# BlueNRG1 register map
Vendor: STMicroelectronics; Series: BlueNRG1; File version: 2.0.0
CPU: CM0 r0p0, little endian, no MPU, no FPU, 2 interrupt priority bits
Registers are 32-bit, read-write, reset 0x0 unless marked. A register's access mark holds for its fields unless they carry their own. Offsets are from the block's base; [hi:lo] are bit positions; 'fields as' and 'values as' point back to an identical list; <NAME> marks a mode.

## I2C2
Base 0x40A00000
Same registers: I2C1 0x40B00000
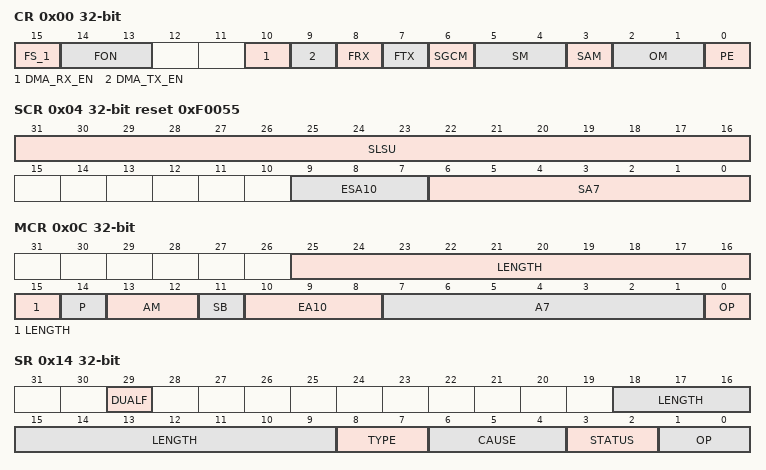
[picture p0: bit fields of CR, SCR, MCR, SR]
0x00 CR — I2C Control register
  [15] FS_1 — Force stop enable bit. When set to 1b, the STOP condition is generated.<ul><li>0: Force stop disabled.</li><li>1: Enable force stop.</li></ul>
    0=DISABLE (Force stop disable); 1=ENABLE (Force stop enable)
  [14:13] FON — Filtering on sets the digital filters on the SDA, SCL line, according to the I2C bus requirements, when standard open-drain pads are used:<ul><li>00b: No digital filters are inserted.</li><li>01b: Digital filters (filter 1 ck wide spikes) are inserted.</li><li>10b: Digital filters (filter 2 ck wide spikes) are inserted.</li><li>11b: Digital filters (filter 4 ck wide spikes) are inserted.</li></ul>
    0=NONE (No digital filters are inserted); 1=CK1_SPIKES (Digital filters (filter 1 ck wide spikes) are inserted); 2=CK2_SPIKES (Digital filters (filter 2 ck wide spikes) are inserted); 3=CK4_SPIKES (Digital filters (filter 4 ck wide spikes) are inserted)
  [10] DMA_RX_EN — Enables the DMA RX interface.<ul><li>0: Idle state, the DMA RX interface is disabled.</li><li>1: Run state, the DMA RX interface is enabled.</li></ul>On the completion of the DMA transfer, the DMA RX interface is automatically turned off clearing this bit when the end of transfer signal coming from the DMA is raised. DMA_TX_EN and DMA_RX_EN must not enabled at the same time.
    0=DISABLE (DMA RX interface disable); 1=ENABLE (DMA RX interface enable)
  [9] DMA_TX_EN — Enables the DMA TX interface.<ul><li>0: Idle state, the DMA TX interface is disabled.</li><li>1: Run state, the DMA TX interface is enabled.</li></ul>On the completion of the DMA transfer, the DMA TX interface is automatically turned off clearing this bit when the end of transfer signal coming from the DMA is raised. DMA_TX_EN and DMA_RX_EN must not enabled at the same time.
    0=DISABLE (DMA TX interface disable); 1=ENABLE (DMA TX interface enable)
  [8] FRX write-1-sets — FRX flushes the receive circuitry (FIFO, fsm).The configuration of the I2C node (register setting) is not affected by the flushing operation. The flushing operation is performed on modules working on different clock domains (system and I2C clocks) and needs several system clock cycles before to be completed. Upon completion, the I2C node (internal logic) clears this bit. The application must not access the Rx FIFO during the flushing operation and should poll on this bit waiting for the completion.<ul><li>0: Flush operation is completed (I2C controller clears the bit).</li><li>1: Flush operation is started and in progress (set by application).</li></ul>
  [7] FTX write-1-sets — FTX flushes the transmit circuitry (FIFO, fsm). The configuration of the I2C node (register setting) is not affected by the flushing operation. The flushing operation is performed on modules working on different clock domains (system and I2C clocks) and needs several system clock cycles before being completed. Upon completion, the I2C node (internal logic) clears this bit. The application must not access the Tx FIFO during the flushing operation and should poll on this bit waiting for completion.<ul><li>0: Flush operation is completed (I2C controller clears the bit).</li><li>1: Flush operation is started and in progress (set by application).</li></ul>
  [6] SGCM — Slave general call mode defines the operating mode of the slave controller when a general call is received. This setting does not affect the hardware general call that is always managed in transparent mode.<ul><li>0: transparent mode, the slave receiver recognizes the general call but any action is taken by the hardware after the decoding of the message included in the Rx FIFO.</li><li>1: direct mode, the slave receiver recognizes the general call and executes directly (without software intervention) the related actions. Only the status code word is stored in the I2C_SR register for notification to the application.</li></ul>
    0=TRANSPARENT_MODE (Transparent mode, the slave receiver recognizes the general call ut any action is taken by software after the decoding of the message included in the Rx FIFO); 1=DIRECT_MODE (Direct mode, the slave receiver recognizes the general call and executes directly (without software intervention) the related actions. Only the status code word is stored in the SR register for notification to the application)
  [5:4] SM — Speed mode. SM defines the speed mode related to the serial bit rate:<ul><li>0: Standard mode (up to 100 K/s).</li><li>1: Fast mode (up to 400 K/s).</li></ul>
    0=STANDARD_MODE (Standard mode (up to 100 K/s)); 1=FAST_MODE (Fast mode (up to 400 K/s))
  [3] SAM — Slave addressing mode. SAM defines the slave addressing mode when the peripheral works in slave or master/slave mode. The received address is compared with the content of the register SCR.<ul><li>0: 7-bit addressing mode.</li><li>1: 10-bit addressing mode.</li></ul>
    0=ADDR_7BIT (7-bit addressing mode); 1=ADDR_10BIT (10-bit addressing mode)
  [2:1] OM — Select the operating mode:<ul><li>00b: Slave mode. The peripheral can only respond (transmit/receive) when addressed by a master device</li><li>01b: Master mode. The peripheral works in a multi-master system where itself cannot be addressed by another master device. It can only initiate a new transfer as master device.</li><li>10b: Master/slave mode. The peripheral works in a multi-master system where itself can be addressed by another master device, besides to initiate a transfer as master device.</li></ul>
    0=SLAVE (The peripheral can only respond (transmit/receive) when addressed by a master device); 1=MASTER (The peripheral works in a multi-master system where itself cannot be addressed by another master device. It can only initiate a new transfer as master device); 2=MASTER_SLAVE (The peripheral works in a multi-master system where itself can be addressed by another master device, besides to initiate a transfer as master device)
  [0] PE — I2C enable disable:<ul><li>0: I2C disable.</li><li>1: I2C enable.</li></ul>This bit when deasserted works as software reset for I2C peripheral.
    0=DISABLE (I2C disable); 1=ENABLE (I2C enable)
0x04 SCR reset 0xF0055 — I2C Slave Control register
  [31:16] SLSU — Slave data setup time. SLSU defines the data setup time after SCL clock stretching in terms of i2c_clk cycles. Data setup time is actually equal to SLSU-1 clock cycles. The typical values for i2c_clk of 16 MHz are SLSU = 5 in standard mode and SLSU = 3 in fast modes.
  [9:7] ESA10 — Extended slave address 10-bit. ESA10 includes the extension (MSB bits) to the SA7 register field in case of slave addressing mode set to 10-bit
  [6:0] SA7 — Slave address 7-bit. SA7 includes the slave address 7-bit or the LSB bits of the slave address 10-bit
0x0C MCR — I2C master control register
  [25:15] LENGTH — Transaction length. Defines the length, in terms of the number of bytes to be transmitted (MW) or received (MR). In case of write operation, the payload is stored in the Tx FIFO. A transaction can be larger than the Tx FIFO size. In case of read operation the length refers to the number of bytes to be received before generating a not-acknowledge response. A transaction can be larger than the Rx FIFO size. The I2C clock line is stretched low until the data in Rx FIFO are consumed.
  [14] P — Stop condition:<ul><li>0: The current transaction is not terminated by a STOP condition. A repeated START condition is generated on the next operation which is required to avoid to stall the I2C line.</li><li>1: The current transaction is terminated by a STOP condition.</li></ul>
  [13:12] AM — Address type:<ul><li>00b: The transaction is initiated by a general call command. In this case the fields OP, A7, EA10 are "don't care".</li><li>01b: The transaction is initiated by the 7-bit address included in the A7 field.</li><li>10b: The transaction is initiated by the 10-bit address included in the EA10 and A7 fields.</li></ul>
    0=GENERAL_CALL (The transaction is initiated by a general call command); 1=BIT7_ADDRESS (The transaction is initiated by the 7-bit address included in the A7 field); 2=BIT10_ADDRESS (The transaction is initiated by the 10-bit address included in the EA10 and A7 fields)
  [11] SB — Start byte:<ul><li>0: The start byte procedure is not applied to the current transaction.</li><li>1: The start byte procedure is prefixed to the current transaction.</li></ul>
  [10:8] EA10 — Extended address. Includes the extension (MSB bits) of the field A7 used to initiate the current transaction
  [7:1] A7 — Address. Includes the 7-bit address or the LSB bits of the10-bit address used to initiate the current transaction
  [0] OP — Operation<ul><li>0: Indicates a master write operation.</li><li>1: Indicates a master read operation.</li></ul>
    0=MASTER_WRITE (Indicates a master write operation); 1=MASTER_READ (Indicates a master read operation)
0x10 TFR 8-bit — I2C transmit FIFO register
  [7:0] TDATA — Transmission Data. TDATA contains the payload related to a master write or read-from-slave operation to be written in the Tx FIFO. TDATA(0) is the first LSB bit transmitted over the I2C line.<p>In case of master write operation, the Tx FIFO shall be preloaded otherwise the I2C controller cannot start the operation until data are available.</p><p>In case of read-from-slave operation, when the slave is addressed, the interrupt RISR:RFSR bit is asserted and the CPU shall download the data in the FIFO. If the FIFO is empty and the I2C master is still requiring data, a new request (RISR:RFSE interrupt bit) is asserted to require additional data to the CPU. The slave controller stretches the I2C clock line when no data are available for transmission. Since the Tx FIFO could contain some pending data related to the previous transfer (the transfer length may be unknown to the slave controller), the Tx FIFO is self-flushed before asserting the I2C_RISR:RFSR bit. Upon completion of the read-from-slave operation the interrupt bit I2C_RISR:STD is asserted and the related status of the operation is stored in the I2C_SR register. In CPU mode, the FIFO management shall be based on the assertion of the interrupt bit RISR:TXFNE, related to the nearly-empty threshold.</p><p>In DMA mode, the single/burst requests are automatically executed based on the number of entries available in the TX FIFO and the related destination burst size programmed in the I2C_DMAR:DBSIZE_TX register field. The DMA requests are terminated at the end of the I2C read operation (notacknowledge received by the master) by a dummy last single/burst request.</p>
0x14 SR ro — I2C status register
  [29] DUALF — Dual flag (slave mode):<ul><li>0: Received address matched with slave address (SA7).</li><li>1: Received address matched with dual slave address (DSA7).</li></ul>Cleared by hardware after a Stop condition or repeated Start condition, bus error or when PE=0.
    0=DUAL_SLAVE_ADDR_OFF (Received address matched with slave address (SA7)); 1=DUAL_SLAVE_ADDR_ON (Received address matched with dual slave address (DSA7))
  [18:9] LENGTH — Transfer length. For an MR, WTS operation the LENGTH field defines the actual size of the subsequent payload, in terms of number of bytes. For an MW, RFS operation the LENGTH field defines the actual number of bytes transferred by the master/slave device. For a WTS operation if the transfer length exceeds 2047 bytes, the operation is stopped by the slave returning a NACK handshake and the flag OVFL is set. For an RFS operation if the transfer length exceeds 2047 bytes, the operation continues normally but the LENGTH field is reset to 0.
  [8:7] TYPE — Receive type. Valid only for the operation WTS:<ul><li>00b: FRAME: The slave has received a normal frame.</li><li>01b: GCALL: The slave has received a general call. If the it I2C_CR:SGCM is set to 1, the general call is directly executed without software intervention and only the control code word is reported in FIFO (LENGTH =0).</li><li>10b: HW_GCALL: The slave has received a hardware general call.</li></ul>
    0=FRAME (The slave has received a normal frame); 1=GCALL (The slave has received a general call); 2=HW_GCALL (The slave has received a hardware general call)
  [6:4] CAUSE — Abort cause. This field is valid only when the STATUS field contains the ABORT tag. Others: RESERVED. <ul><li>000b: NACK_ADDR: The master receives a not-acknowledge after the transmission of the address. Valid for the operation MW, MR.</li><li>001b: NACK_DATA: The master receives a not-acknowledge during the data phase of a MW operation. Valid for the operation MW.</li><li>011b: ARB_LOST: The master loses the arbitration during a MW or MR operation. Valid for the operation MW, MR.</li><li>100b: BERR_START: Slave restarts, a START Condition occurs while the byte transfer is not terminated.</li><li>101b: BERR_STOP: Slave reset, a STOP Condition while the byte transfer is not terminated.</li><li>110b: OVFL: The slave receives a frame related to the WTS operation longer than the maximum size = 2047 bytes. In this case the slave device returns a NACK to complete the data transfer. Valid for WTS operation</li></ul>
    0=NACK_ADDR (The master receives a not-acknowledge after the transmission of the address); 1=NACK_DATA (The master receives a not-acknowledge during the data phase of a MW operation); 3=ARB_LOST (The master loses the arbitration during a MW or MR operation); 4=BERR_START (Slave restarts, a START Condition occurs while the byte transfer is not terminated); 5=BERR_STOP (Slave reset, a STOP Condition while the byte transfer is not terminated); 6=OVFL (The slave receives a frame related to the WTS operation longer than the maximum size = 2047 bytes)
  [3:2] STATUS — Controller status. Valid for the operations MW, MR, WTS RFS:<ul><li>00b: NOP: No operation is in progress.</li><li>01b: ON_GOING: An operation is ongoing.</li><li>10b: OK: The operation (OP field) has been completed successfully.</li><li>11b: ABORT: The operation (OP field) has been aborted due to the occurrence of the event described in the CAUSE field.</li></ul>
    0=NOP (No operation is in progress); 1=ON_GOING (An operation is ongoing); 2=OK (The operation (OP field) has been completed successfully); 3=ABORT (The operation (OP field) has been aborted due to the occurrence of the event descried in the CAUSE field)
  [1:0] OP — Operation:<ul><li>00b: MW: master write operation.</li><li>01b: MR: master read operation.</li><li>10b: WTS: write-to-slave operation.</li><li>11b: RFS: read-from-slave operation.</li></ul>
    0=MW (Master write operation); 1=MR (Master read operation); 2=WTS (Write to slave operation); 3=RFS (Read from slave operation)
0x18 RFR 8-bit ro — I2C receive FIFO register
  [7:0] RDATA — Receive data. RDATA contains the received payload, related to a master read or write-to-slave operation, to be read from the Rx FIFO. The RDATA(0) is the first LSB bit received over the I2C line. In case the FIFO is full, the I2C controller stretches automatically the I2C clock line until a new entry is available.<p>For a write-to-slave operation, when the slave is addressed, the interrupt I2C_RISR:WTSR bit is asserted for notification to the CPU. In CPU mode the FIFO management shall be based on the assertion of the interrupt bit I2C_RISR:RXFNF, related to the nearly-full threshold.</p><p>In DMA mode, the single requests are automatically executed based on the number of entries contained in the Rx FIFO.</p>
0x1C TFTR 16-bit — I2C transmit FIFO threshold register
  [9:0] THRESH_TX — Threshold TX, contains the threshold value, in terms of number of bytes, of the Tx FIFO.<p>When the number of entries of the Tx FIFO is less or equal than the threshold value, the interrupt bit I2C_RISR:TXFNE is set in order to request the loading of data to the application.</p>
0x20 RFTR 16-bit — I2C receive FIFO threshold register
  [9:0] THRESH_RX — Threshold RX, contains the threshold value, in terms of number of bytes, of the Rx FIFO.<p>When the number of entries of the RX FIFO is greater than or equal to the threshold value, the interrupt bit RISR:RXFNF is set in order to request the download of received data to the application. The application shall download the received data based on the threshold. (RISR:RXFNF).</p>
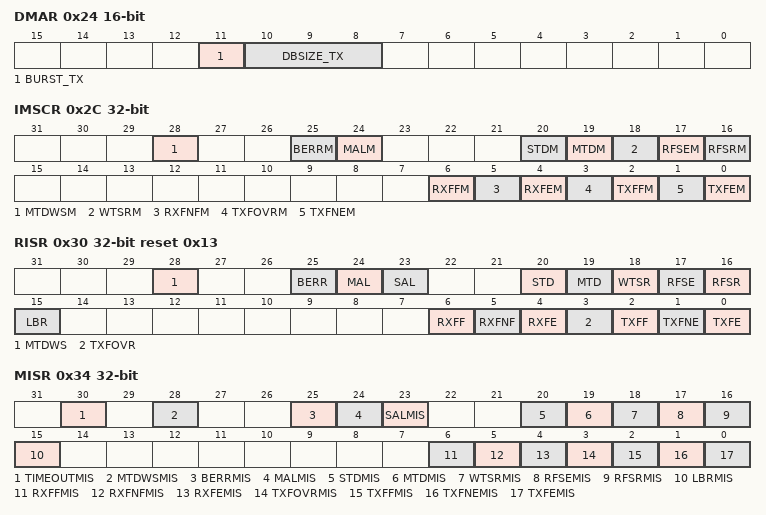
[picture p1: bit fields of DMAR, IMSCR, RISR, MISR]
0x24 DMAR 16-bit — I2C DMA register
  [11] BURST_TX — Defines the type of DMA request generated by the DMA TX interface.<ul><li>0: Single request mode. Transfers a single data (one byte) in the TX FIFO.</li><li>1: Burst request mode. Transfers a programmed burst of data according to DBSIZE_TX field.</li></ul>When the burst mode is programmed, the DMA transfer can be completed by one or more single requests as required.
  [10:8] DBSIZE_TX — Destination burst size. This register field is valid only if the BURST_TX bit is set to '1'. If burst size is smaller than the transaction length, only single request are generated.
0x28 BRCR 16-bit reset 0x8 — I2C Baud-rate counter register
  [15:0] BRCNT — Baud rate counter. BRCNT defines the counter value used to set up the I2C baud rate in standard and fast mode, when the peripheral is operating in master mode.
0x2C IMSCR — I2C interrupt mask set/clear register
  [28] MTDWSM — Master Transaction done without stop mask. MTDWSM enables the interrupt bit MTDWS:<ul><li>0: MTDWS interrupt is disabled.</li><li>1: MTDWS interrupt is enabled.</li></ul>
    0=DISABLE (Disable the interrupt mask); 1=ENABLE (Enable the interrupt mask)
  [25] BERRM — Bus Error mask. BERRM enables the interrupt bit BERR:<ul><li>0: BERR interrupt is disabled.</li><li>1: BERR interrupt is enabled.</li></ul>
    values as MTDWSM
  [24] MALM — Master Arbitration lost mask. MALM enables the interrupt bit MAL:<ul><li>0: MAL interrupt is disabled.</li><li>1: MAL interrupt is enabled.</li></ul>
    values as MTDWSM
  [20] STDM — Slave Transaction done mask. STDM enables the interrupt bit STD:<ul><li>0: STDM interrupt is disabled.</li><li>1: STDM interrupt is enabled.</li></ul>
    values as MTDWSM
  [19] MTDM — Master Transaction done mask. MTDM enables the interrupt bit MTD:<ul><li>0: MTD interrupt is disabled.</li><li>1: MTD interrupt is enabled.</li></ul>
    values as MTDWSM
  [18] WTSRM — Write-to-Slave request mask. WTSRM enables the interrupt bit WTSR:<ul><li>0: WTSR interrupt is disabled.</li><li>1: WTSR interrupt is enabled.</li></ul>
    values as MTDWSM
  [17] RFSEM — Read-from-Slave empty mask. RFSEM enables the interrupt bit RFSE:<ul><li>0: RFSE interrupt is disabled.</li><li>1: RFSE interrupt is enabled.</li></ul>
    values as MTDWSM
  [16] RFSRM — Read-from-Slave request mask. RFSRM enables the interrupt bit RFSR:<ul><li>0: RFSR interrupt is disabled.</li><li>1: RFSR interrupt is enabled.</li></ul>
    0=DISABLE (Disable the interrupt mask); 1=ENABLE (Enable the interrupt mask); 0=DISABLE (Disable the interrupt mask); 1=ENABLE (Enable the interrupt mask)
  [6] RXFFM — RX FIFO full mask. RXFFM enables the interrupt bit RXFF:<ul><li>0: RXFF interrupt is disabled.</li><li>1: RXFF interrupt is enabled.</li></ul>
    values as MTDWSM
  [5] RXFNFM — RX FIFO nearly full mask. RXNFM enables the interrupt bit RXNF:<ul><li>0: RXNF interrupt is disabled.</li><li>1: RXNF interrupt is enabled</li></ul>
    values as MTDWSM
  [4] RXFEM — RX FIFO empty mask. RXFEM enables the interrupt bit RXFE:<ul><li>0: RXFE interrupt is disabled.</li><li>1: RXFE interrupt is enabled.</li></ul>
    values as MTDWSM
  [3] TXFOVRM — TX FIFO overrun mask. TXOVRM enables the interrupt bit TXOVR:<ul><li>0: TXOVR interrupt is disabled.</li><li>1: TXOVR interrupt is enabled.</li></ul>
    values as MTDWSM
  [2] TXFFM — TX FIFO full mask. TXFFM enables the interrupt bit TXFF:<ul><li>0: TXFF interrupt is disabled.</li><li>1: TXFF interrupt is enabled.</li></ul>
    values as MTDWSM
  [1] TXFNEM — TX FIFO nearly empty mask. TXFNEM enables the interrupt bit TXFNE:<ul><li>0: TXFNE interrupt is disabled.</li><li>1: TXFNE interrupt is enabled.</li></ul>
    values as MTDWSM
  [0] TXFEM — TX FIFO empty mask. TXFEM enables the interrupt bit TXFE:<ul><li>0: TXFE interrupt is disabled.</li><li>1: TXFE interrupt is enabled.</li></ul>
    values as MTDWSM
0x30 RISR ro reset 0x13 — I2C raw interrupt status register
  [28] MTDWS — Master transaction done without stop. MTDWS is set when a master operation (write or read) has been executed and a stop (MCR:P field) is not programmed. The application shall read the related transaction status (SR register), the pending data in the RX FIFO (only for a master read operation) and clear this interrupt (transaction acknowledgment). A subsequent master operation can be issued (by writing the MCR register) after clearing this interrupt. A subsequent slave operation will be notified (RISR:WTSR and RISR:RFSR interrupt bits assertion) after clearing this interrupt, meanwhile the I2C clock line will be stretched low. This interrupt is cleared by setting the related bit of the ICR register:<ul><li>0: Master transaction acknowledged.</li><li>1: Master transaction done (ready for acknowledgment) and stop is not applied into the I2C bus.</li></ul>
  [25] BERR — Bus Error. BERR is set when an unexpected Start/Stop condition occurs during a transaction. The related actions are different, depending on the type of operation in progress.The status code word in the SR contains a specific error tag (CAUSE field) for this error condition. This interrupt is cleared by setting the related bit of the ICR register.<ul><li>0: No bus error detection.</li><li>1: Bus error detection.</li></ul>
  [24] MAL — Master arbitration lost. MAL is set when the master loses the arbitration. The status code word in the SR contains a specific error tag (CAUSE field) for this error condition. A collision occurs when 2 stations transmit simultaneously 2 opposite values on the serial line. The station that is pulling up the line, identifies the collision reading a 0 value on the sda_in signal, stops the transmission, leaves the bus and waits for the idle state (STOP condition received) on the bus line before retrying the same transaction. The station which transmits the first unique zero wins the bus arbitration. This interrupt is cleared by setting the related bit of the ICR register.<ul><li>0: No master arbitration lost.</li><li>1: Master arbitration lost.</li></ul>
  [23] SAL — Slave Arbitration lost. SAL is set when the slave loses the arbitration during the data phase. A collision occurs when 2 devices transmit simultaneously 2 opposite values on the serial data line. The device that is pulling up the line, identifies the collision reading a 0 value on the sda_in signal, stops the transmission, releases the bus and waits for the idle state (STOP condition received) on the bus line. The device which transmits the first unique zero wins the bus arbitration. This interrupt is cleared by setting the related bit of the ICR register.<ul><li>0: No slave arbitration lost.</li><li>1: Slave arbitration lost.</li></ul>
  [20] STD — Slave Transaction done. STD is set when a slave operation (write-to-slave or read-from-slave) has been executed. The application shall read the related transaction status (SR register), the pending data in the RX FIFO (only for a write-to-slave operation) and clear this interrupt (transaction acknowledgment). A subsequent slave operation will be notified (RISR:WTSR and RISR:RFSR interrupt bits assertion) after clearing this interrupt, meanwhile the I2C clock line will be stretched low. A subsequent master operation can be issued (by writing the MCR register) after clearing this interrupt. This interrupt is cleared by setting the related bit of the ICR register:<ul><li>0: Slave transaction acknowledged.</li><li>1: Slave transaction done (ready for acknowledgment).</li></ul>
  [19] MTD — Master Transaction done. MTD is set when a master operation (master write or master read) has been executed after a stop condition. The application shall read the related transaction status (SR register), the pending data in the RX FIFO (only for a master read operation) and clear this interrupt (transaction acknowledgment). A subsequent master operation can be issued (writing the MCR register) after the clearing of this interrupt. A subsequent slave operation will be notified (RISR:WTSR and RISR:RFSR interrupt bits assertion) after clearing this interrupt, meanwhile the I2C clock line will be stretched low. This interrupt is cleared by setting the related bit of the ICR register.<ul><li>0: Master transaction acknowledged.</li><li>1: Master transaction done (ready for acknowledgment).</li></ul>
  [18] WTSR — Write-to-Slave request. WTSR is set when a write-to-slave operation is received (I2C slave is addressed) from the I2C line. This notification can be used by the application to program the DMA descriptor when required. This interrupt is cleared by setting the related bit of the ICR register:<ul><li>0: No write-to-slave request pending.</li><li>1: Write-to-slave request is pending.</li></ul>
  [17] RFSE — Read-from-Slave empty. RFSE is set when a read-from-slave operation is in progress and TX FIFO is empty. On the assertion of this interrupt, the CPU shall download in TX FIFO the data required for the slave operation. This bit is self-cleared by writing in TX FIFO. At the end of the read-from-slave operation this bit is cleared although the TX FIFO is empty.<ul><li>0: TX FIFO is not empty.</li><li>1: TX FIFO is empty with the read-from-slave operation in progress.</li></ul>
  [16] RFSR — Read-from-slave request. RFSR is set when a read-from-slave "Slavetransmitter" request is received (I2C slave is addressed) from the I2C line. On the assertion of this interrupt the TX FIFO is flushed (pending data are cleared) and the CPU shall put the data in TX FIFO. This bit is self-cleared by writing data in FIFO. In case the FIFO is empty before the completion of the read operation, the RISR:RFSE interrupt bit is set.This interrupt is cleared by setting the related bit of the ICR register.<ul><li>0: Read-from-slave request has been served.</li><li>1: Read-from-slave request is pending.</li></ul>
  [15] LBR — Length number of bytes received. LBR is set in case of MR or WTS and when the number of bytes received is equal to the transaction length programmed in the MCR:LENGTH (master mode) or SMB_SCR:LENGTH (slave mode). On the assertion of this interrupt and when the bit CR:FRC_STRTCH is set, the hardware starts clock stretching, the CPU shall download the data byte (Command code, Byte Count, Data...) from RX FIFO, re-set the expected length of the transaction in SMB_SCR:LENGTH and clear the interrupt. When clearing this interrupt the hardware continues the transfer. This interrupt is cleared by setting the related bit of the ICR register.<ul><li>0: Length number of bytes is not received.</li><li>1: Length number of bytes is received.</li></ul>
  [6] RXFF — RX FIFO full. RXFF is set when a full condition occurs in RX FIFO. This bit is self-cleared when the data are read from the RX FIFO.<ul><li>0: RX FIFO is not full.</li><li>1: RX FIFO is full.</li></ul>
  [5] RXFNF — RX FIFO nearly full. RXFNF is set when the number of entries in RX FIFO is greater than or equal to the threshold value programmed in the RFTR:THRESHOLD_RX register. Its self-cleared when the threshold level is under the programmed threshold:<ul><li>0: Number of entries in the RX FIFO less than the RFTR:THRESHOLD_RX register.</li><li>1: Number of entries in the RX FIFO greater than or equal to the RFTR:THRESHOLD_RX register.</li></ul>
  [4] RXFE — RX FIFO empty. RXFE is set when the RX FIFO is empty. This bit is self-cleared when the slave RX FIFO is not empty:<ul><li>0: RX FIFO is not empty..</li><li>1: RX FIFO is empty..</li></ul>
  [3] TXFOVR — TX FIFO overrun. TXFOVR is set when a write operation in TX FIFO is performed and TX FIFO is full. The application must avoid an overflow condition by a proper data flow control. Anyway in case of overrun, the application shall flush the transmitter (CR:FTX bit to set) because the TX FIFO content is corrupted (at least one word has been lost in FIFO). This interrupt is cleared by setting the related bit of the ICR register:<ul><li>0: No overrun condition occurred in TX FIFO.</li><li>1: Overrun condition occurred in TX FIFO.</li></ul>
  [2] TXFF — TX FIFO full. TXFF is set when a full condition occurs in TX FIFO. This bit is self-cleared when the TX FIFO is not full:<ul><li>0: TX FIFO is not full.</li><li>1: TX FIFO is full.</li></ul>
  [1] TXFNE — TX FIFO nearly empty. TXFNE is set when the number of entries in TX FIFO is less than or equal to the threshold value programmed in the I2C_TFTR:THRESHOLD_TX register. It is self-cleared when the threshold level is over the programmed threshold.<ul><li>0: Number of entries in TX FIFO greater than the TFTR:THRESHOLD_TX register.</li><li>1: Number of entries in TX FIFO less than or equal to the TFTR:THRESHOLD_TX register.</li></ul>
  [0] TXFE — TX FIFO empty. TXFE is set when TX FIFO is empty. This bit is self-cleared by writing in TX FIFO.<ul><li>0: TX FIFO is not empty.</li><li>1: TX FIFO is empty.</li></ul>
0x34 MISR ro — I2C masked interrupt status register
  [30] TIMEOUTMIS — Timeout or Tlow error masked interrupt status.<ul><li>0: No timeout error.</li><li>1: SCL remained LOW for 25 ms (Timeout).</li></ul>
  [28] MTDWSMIS — Master Transaction done without stop masked interrupt status.<ul><li>0: Master transaction acknowledged.</li><li>1: Master transaction done (ready for acknowledgment) and stop is not applied into the I2C bus.</li></ul>
  [25] BERRMIS — Bus Error masked interrupt status.<ul><li>0: No bus error detection.</li><li>1: Bus error detection.</li></ul>
  [24] MALMIS — Master Arbitration lost masked interrupt status.<ul><li>0: No master arbitration lost.</li><li>1: Master arbitration lost.</li></ul>
  [23] SALMIS — Slave Arbitration lost masked interrupt status.<ul><li>0: No slave arbitration lost.</li><li>1: Slave arbitration lost.</li></ul>
  [20] STDMIS — Slave Transaction done masked interrupt status.<ul><li>0: Slave transaction acknowledged.</li><li>1: Slave transaction done (ready for acknowledgment).</li></ul>
  [19] MTDMIS — Master Transaction done masked interrupt status.<ul><li>0: Master transaction acknowledged.</li><li>1: Master transaction done (ready for acknowledgment).</li></ul>
  [18] WTSRMIS — Write-to-Slave request masked interrupt status.<ul><li>0: No write-to-slave request pending.</li><li>1: Write-to-slave request is pending.</li></ul>
  [17] RFSEMIS — Read-from-Slave empty masked interrupt status.<ul><li>0: TX FIFO is not empty.</li><li>1: TX FIFO is empty with the read-from-slave operation in progress.</li></ul>
  [16] RFSRMIS — Read-from-Slave request masked interrupt status.<ul><li>0: Read-from-slave request has been served.</li><li>1: Read-from-slave request is pending.</li></ul>
  [15] LBRMIS — Length number of bytes received masked interrupt status.<ul><li>0: Length number of bytes is not received.</li><li>1: Length number of bytes is received.</li></ul>
  [6] RXFFMIS — RX FIFO full masked interrupt status.<ul><li>0: RX FIFO is not full.</li><li>1: RX FIFO is full.</li></ul>
  [5] RXFNFMIS — RX FIFO nearly full masked interrupt status.<ul><li>0: Number of entries in the RX FIFO less than the RFTR:THRESHOLD_RX register.</li><li>1: Number of entries in the RX FIFO greater than or equal to the RFTR:THRESHOLD_RX register.</li></ul>
  [4] RXFEMIS — RX FIFO empty masked interrupt status.<ul><li>0: RX FIFO is not empty.</li><li>1: RX FIFO is empty..</li></ul>
  [3] TXFOVRMIS — Tx FIFO overrun masked interrupt status.<ul><li>0: No overrun condition occurred in TX FIFO.</li><li>1: Overrun condition occurred in TX FIFO.</li></ul>
  [2] TXFFMIS — Tx FIFO full masked interrupt status.<ul><li>0: TX FIFO is not full.</li><li>1: TX FIFO is full.</li></ul>
  [1] TXFNEMIS — TX FIFO nearly empty masked interrupt status.<ul><li>0: Number of entries in TX FIFO greater than the TFTR:THRESHOLD_TX register.</li><li>1: Number of entries in TX FIFO less than or equal to the TFTR:THRESHOLD_TX register.</li></ul>
  [0] TXFEMIS — TX FIFO empty masked interrupt status.<ul><li>0: TX FIFO is not empty.</li><li>1: TX FIFO is empty.</li></ul>
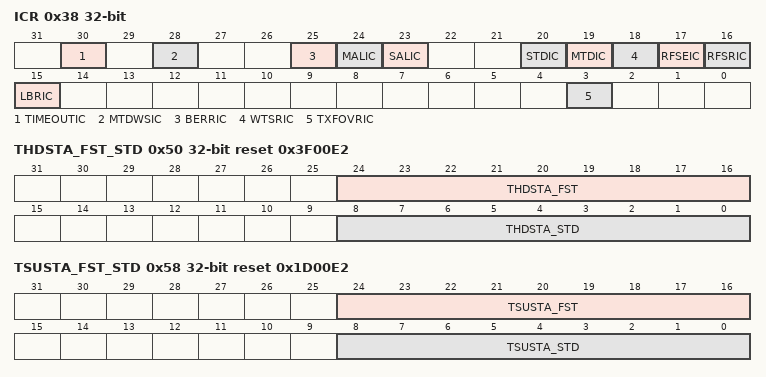
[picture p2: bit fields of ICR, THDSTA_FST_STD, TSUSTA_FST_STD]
0x38 ICR write-1-clears — I2C interrupt clear register
  [30] TIMEOUTIC — Timeout or Tlow error interrupt clear.<ul><li>0: Has no effect.</li><li>1: Clears interrupt pending.</li></ul>
  [28] MTDWSIC — Master Transaction done without stop interrupt clear.<ul><li>0: Has no effect.</li><li>1: Clears interrupt pending.</li></ul>
  [25] BERRIC — Bus Error interrupt clear.<ul><li>0: Has no effect.</li><li>1: Clears interrupt pending.</li></ul>
  [24] MALIC — Master Arbitration lost interrupt clear.<ul><li>0: Has no effect.</li><li>1: Clears interrupt pending.</li></ul>
  [23] SALIC — Slave Arbitration lost interrupt clear.<ul><li>0: Has no effect.</li><li>1: Clears interrupt pending.</li></ul>
  [20] STDIC — Slave Transaction done interrupt clear.<ul><li>0: Has no effect.</li><li>1: Clears interrupt pending.</li></ul>
  [19] MTDIC — Master Transaction done interrupt clear.<ul><li>0: Has no effect.</li><li>1: Clears interrupt pending.</li></ul>
  [18] WTSRIC — Write-to-Slave request interrupt clear.<ul><li>0: Has no effect.</li><li>1: Clears interrupt pending.</li></ul>
  [17] RFSEIC — Read-from-Slave empty interrupt clear.<ul><li>0: Has no effect.</li><li>1: Clears interrupt pending.</li></ul>
  [16] RFSRIC — Read-from-Slave request interrupt clear.<ul><li>0: Has no effect.</li><li>1: Clears interrupt pending.</li></ul>
  [15] LBRIC — Length number of bytes received interrupt clear.<ul><li>0: Has no effect.</li><li>1: Clears interrupt pending.</li></ul>
  [3] TXFOVRIC — Tx FIFO overrun interrupt clear.<ul><li>0: Has no effect.</li><li>1: Clears interrupt pending.</li></ul>
0x4C THDDAT 16-bit reset 0x14 — I2C hold time data
  [8:0] THDDAT — Hold time data value. In master or slave mode, when the I2C controller detects a falling edge in the SCL line, the counter, which is loaded by the THDDAT, is launched. Once the THDDAT value is reached, the data is transferred.
0x50 THDSTA_FST_STD reset 0x3F00E2 — I2C hold time start condition F/S
  [24:16] THDSTA_FST — Hold time start condition value for fast mode. When the start condition is asserted, the decimeter loads the value of THDSTA_FST for fast mode, once the THDSTA_FST value is reached, the SCL line assert slow.
  [8:0] THDSTA_STD — Hold time start condition value for standard mode. When the start condition is asserted, the decimeter loads the value of THDSTA_STD for standard mode, once the THDSTA_STD value is reached, the SCL line asserts low.
0x58 TSUSTA_FST_STD reset 0x1D00E2 — I2C setup time start condition F/S
  [24:16] TSUSTA_FST — Setup time start condition value for fast mode. After a non-stop on the SCL line the decimeter loads the value of TSUSTA_FST according to fast mode. Once the counter is expired the start condition is generated.
  [8:0] TSUSTA_STD — Setup time start condition value for standard mode. After a non-stop on the SCL line the decimeter loads the value of TSUSTA_STD according to standard mode. Once the counter is expired, the start condition is generated.

## Notices in the file
License
